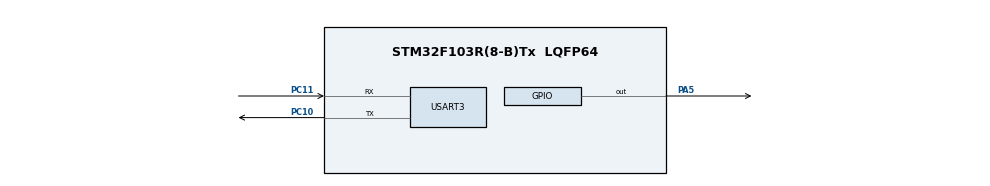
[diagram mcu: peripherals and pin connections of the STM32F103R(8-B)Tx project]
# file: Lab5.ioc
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FREERTOS.Tasks01=blink01,32,128,StartBlink01,Default,NULL,Dynamic,NULL,NULL;RX_CLI,24,128,StartRX_CLI,Default,NULL,Dynamic,NULL,NULL;Status_CLI,16,128,StartStatus_CLI,Default,NULL,Dynamic,NULL,NULL
Mcu.Family=STM32F1
Mcu.Name=STM32F103R(8-B)Tx
Mcu.Package=LQFP64
NVIC.PriorityGroup=NVIC_PRIORITYGROUP_4
NVIC.TIM4_IRQn=true\:0\:0\:false\:false\:true\:false\:false\:true
NVIC.TimeBase=TIM4_IRQn
NVIC.TimeBaseIP=TIM4
PA13.Mode=Serial_Wire
PA13.Signal=SYS_JTMS-SWDIO
PA14.Mode=Serial_Wire
PA14.Signal=SYS_JTCK-SWCLK
PA5.Signal=GPIO_Output
PC10.Mode=Asynchronous
PC10.Signal=USART3_TX
PC11.Mode=Asynchronous
PC11.Signal=USART3_RX
ProjectManager.HeapSize=0x200
ProjectManager.StackSize=0x400
ProjectManager.TargetToolchain=STM32CubeIDE
RCC.APB1Freq_Value=8000000
RCC.APB2Freq_Value=8000000
USART3.VirtualMode=VM_ASYNC
VP_FREERTOS_VS_CMSIS_V2.Mode=CMSIS_V2
VP_SYS_VS_tim4.Mode=TIM4
board=custom

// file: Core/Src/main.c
/* USER CODE BEGIN Header */
/**
  ******************************************************************************
  * @file           : main.c
  * @brief          : Main program body
  ******************************************************************************
  * @attention
  *
  * <h2><center>&copy; Copyright (c) 2020 STMicroelectronics.
  * All rights reserved.</center></h2>
  *
  * This software component is licensed by ST under BSD 3-Clause license,
  * the "License"; You may not use this file except in compliance with the
  * License. You may obtain a copy of the License at:
  *                        opensource.org/licenses/BSD-3-Clause
  *
  ******************************************************************************
  */
/* USER CODE END Header */
#include "main.h"
#include "cmsis_os.h"

/* USER CODE BEGIN Includes */
#include "CLI.h"
//#include <stdio.h>
//#include <string.h>
//#include <stdbool.h>
//#include <stdlib.h>

/* USER CODE END Includes */

UART_HandleTypeDef huart3;

/* Definitions for blink01 */
osThreadId_t blink01Handle;
const osThreadAttr_t blink01_attributes = {
  .name = "blink01",
  .priority = (osPriority_t) osPriorityAboveNormal,
  .stack_size = 128 * 4
};
/* Definitions for RX_CLI */
osThreadId_t RX_CLIHandle;
const osThreadAttr_t RX_CLI_attributes = {
  .name = "RX_CLI",
  .priority = (osPriority_t) osPriorityNormal,
  .stack_size = 128 * 4
};
/* Definitions for Status_CLI */
osThreadId_t Status_CLIHandle;
const osThreadAttr_t Status_CLI_attributes = {
  .name = "Status_CLI",
  .priority = (osPriority_t) osPriorityBelowNormal,
  .stack_size = 128 * 4
};
/* USER CODE BEGIN PV */
uint8_t cliBufferTX[56];
uint8_t cliBufferRX[10];
uint8_t save[40];
int j = 0;
int period = 400;
uint8_t period_str[10];
bool update = false;

const char *CLEAR_SCREEN = "\x1b[2J";
const char *SCROLL_WINDOW = "\x1b[10;r";
const char *GO_TO_SCROLL = "\x1b[10;0H";
const char *GO_TO_TOP = "\x1b[0;0H";
const char *GO_TO_COUNT = "\x1b[0;9H";
const char *HIDE_CURS = "\x1b[?25l";
const char *SHOW_CURS = "\x1b[?25h";
const char *SAVE_CURS = "\x1b[s";
const char *RETURN_CURS = "\x1b[u";

/* USER CODE END PV */

void SystemClock_Config(void);
static void MX_GPIO_Init(void);
static void MX_USART3_UART_Init(void);
void StartBlink01(void *argument);
void StartRX_CLI(void *argument);
void StartStatus_CLI(void *argument);

int main(void)
{

  /* MCU Configuration--------------------------------------------------------*/

  /* Reset of all peripherals, Initializes the Flash interface and the Systick. */
  HAL_Init();

  /* Configure the system clock */
  SystemClock_Config();

  /* Initialize all configured peripherals */
  MX_GPIO_Init();
  MX_USART3_UART_Init();
  /* USER CODE BEGIN 2 */
  printString(CLEAR_SCREEN);
  printString(GO_TO_TOP);
  printString("Welcome to the CLI!\r\n");
  HAL_Delay(2000);

  //Formats the screen to show counter and create a scroll window
  printString(CLEAR_SCREEN);
  printString(GO_TO_TOP);
  printString("period: ");
  printString("400");
  printString("\x1b[9;0H");
  printString("Enter \"period x\" to change the period of the LED flash, where x > 0");
  printString(SCROLL_WINDOW);
  printString(GO_TO_SCROLL);

  printString("\n~>$ ");
  printString(SAVE_CURS);

  /* USER CODE END 2 */

  /* Init scheduler */
  osKernelInitialize();

  /* Create the thread(s) */
  /* creation of blink01 */
  blink01Handle = osThreadNew(StartBlink01, NULL, &blink01_attributes);

  /* creation of RX_CLI */
  RX_CLIHandle = osThreadNew(StartRX_CLI, NULL, &RX_CLI_attributes);

  /* creation of Status_CLI */
  Status_CLIHandle = osThreadNew(StartStatus_CLI, NULL, &Status_CLI_attributes);

  /* Start scheduler */
  osKernelStart();

  /* We should never get here as control is now taken by the scheduler */
  /* Infinite loop */
  while (1)
  {

  }
}

void SystemClock_Config(void)
{
  RCC_OscInitTypeDef RCC_OscInitStruct = {0};
  RCC_ClkInitTypeDef RCC_ClkInitStruct = {0};

  /** Initializes the RCC Oscillators according to the specified parameters
  * in the RCC_OscInitTypeDef structure.
  */
  RCC_OscInitStruct.OscillatorType = RCC_OSCILLATORTYPE_HSI;
  RCC_OscInitStruct.HSIState = RCC_HSI_ON;
  RCC_OscInitStruct.HSICalibrationValue = RCC_HSICALIBRATION_DEFAULT;
  RCC_OscInitStruct.PLL.PLLState = RCC_PLL_NONE;
  if (HAL_RCC_OscConfig(&RCC_OscInitStruct) != HAL_OK)
  {
    Error_Handler();
  }
  /** Initializes the CPU, AHB and APB buses clocks
  */
  RCC_ClkInitStruct.ClockType = RCC_CLOCKTYPE_HCLK|RCC_CLOCKTYPE_SYSCLK
                              |RCC_CLOCKTYPE_PCLK1|RCC_CLOCKTYPE_PCLK2;
  RCC_ClkInitStruct.SYSCLKSource = RCC_SYSCLKSOURCE_HSI;
  RCC_ClkInitStruct.AHBCLKDivider = RCC_SYSCLK_DIV1;
  RCC_ClkInitStruct.APB1CLKDivider = RCC_HCLK_DIV1;
  RCC_ClkInitStruct.APB2CLKDivider = RCC_HCLK_DIV1;

  if (HAL_RCC_ClockConfig(&RCC_ClkInitStruct, FLASH_LATENCY_0) != HAL_OK)
  {
    Error_Handler();
  }
}

static void MX_USART3_UART_Init(void)
{

  huart3.Instance = USART3;
  huart3.Init.BaudRate = 115200;
  huart3.Init.WordLength = UART_WORDLENGTH_8B;
  huart3.Init.StopBits = UART_STOPBITS_1;
  huart3.Init.Parity = UART_PARITY_NONE;
  huart3.Init.Mode = UART_MODE_TX_RX;
  huart3.Init.HwFlowCtl = UART_HWCONTROL_NONE;
  huart3.Init.OverSampling = UART_OVERSAMPLING_16;
  if (HAL_UART_Init(&huart3) != HAL_OK)
  {
    Error_Handler();
  }

}

static void MX_GPIO_Init(void)
{
  GPIO_InitTypeDef GPIO_InitStruct = {0};

  /* GPIO Ports Clock Enable */
  __HAL_RCC_GPIOA_CLK_ENABLE();
  __HAL_RCC_GPIOC_CLK_ENABLE();

  /*Configure GPIO pin Output Level */
  HAL_GPIO_WritePin(GPIOA, GPIO_PIN_5, GPIO_PIN_RESET);

  /*Configure GPIO pin : PA5 */
  GPIO_InitStruct.Pin = GPIO_PIN_5;
  GPIO_InitStruct.Mode = GPIO_MODE_OUTPUT_PP;
  GPIO_InitStruct.Pull = GPIO_NOPULL;
  GPIO_InitStruct.Speed = GPIO_SPEED_FREQ_LOW;
  HAL_GPIO_Init(GPIOA, &GPIO_InitStruct);

}

void StartBlink01(void *argument)
{
  /* USER CODE BEGIN 5 */
  /* Infinite loop */
  for(;;)
  {
	  HAL_GPIO_TogglePin(GPIOA, GPIO_PIN_5);

      osDelay(period);
  }
  osThreadTerminate(NULL);
  /* USER CODE END 5 */
}

void StartRX_CLI(void *argument)
{
  /* USER CODE BEGIN StartRX_CLI */

  /* Infinite loop */
  for(;;)
  {
	  if(HAL_UART_Receive(&huart3, cliBufferRX, 1, 300) == HAL_OK)
	  {
		  printString(RETURN_CURS);
		  printString(SHOW_CURS);

		  copyCharTo((char *)cliBufferRX, (char *)save, j);
		  printString(SAVE_CURS);
		  //backspace incidence
		  if(cliBufferRX[0] == '\b')
		  {
			  j--;
		  }
		  else
		  {
			  j++;
		  }

		  //when enter is hit execute the command
		  if(isCompleteLine((char *)cliBufferRX))
		  {
			  char *cmd;
			  char *token;

			  printString("\r\n");
			  while(j < 20 && save[j] != '\0')
			  {
				  save[j] = '\0';
				  j++;
			  }

			  token = strtok((char *)save, " ");
			  cmd = token;
			  token = strtok(NULL, " ");
			  if(strcmp(cmd, "period") == 0 && atoi(token) > 0)
			  {
				  period = atoi(token);
				  update = true;
			  }
			  else if(save[0] != '\r')
			  {
				  printString("Invalid input. Try again.");
			  }
			  printString("\r\n");

			  j = 0;
			  for(int i = 0; i < 20; i++)
			  {
				  save[i] = '\0';
			  }
			  printString("\n~>$ ");

			  printString(SAVE_CURS);

			  osDelay(10);
		  }
	  }
  }
  osThreadTerminate(NULL);
  /* USER CODE END StartRX_CLI */
}

void StartStatus_CLI(void *argument)
{
  /* USER CODE BEGIN StartStatus_CLI */
  /* Infinite loop */
  for(;;)
  {

	  if(update == true)
	  {
		  sprintf((char *)period_str, "%d", period);
		  printString(HIDE_CURS);
		  printString(GO_TO_COUNT);
		  printString("                           ");
		  printString(GO_TO_COUNT);
		  printString((const char *)period_str);
		  update = false;
	  }
	  osDelay(10);
  }
  osThreadTerminate(NULL);
  /* USER CODE END StartStatus_CLI */
}

void HAL_TIM_PeriodElapsedCallback(TIM_HandleTypeDef *htim)
{
  if (htim->Instance == TIM4) {
    HAL_IncTick();
  }
}

void Error_Handler(void)
{
}

/************************ (C) COPYRIGHT STMicroelectronics *****END OF FILE****/
